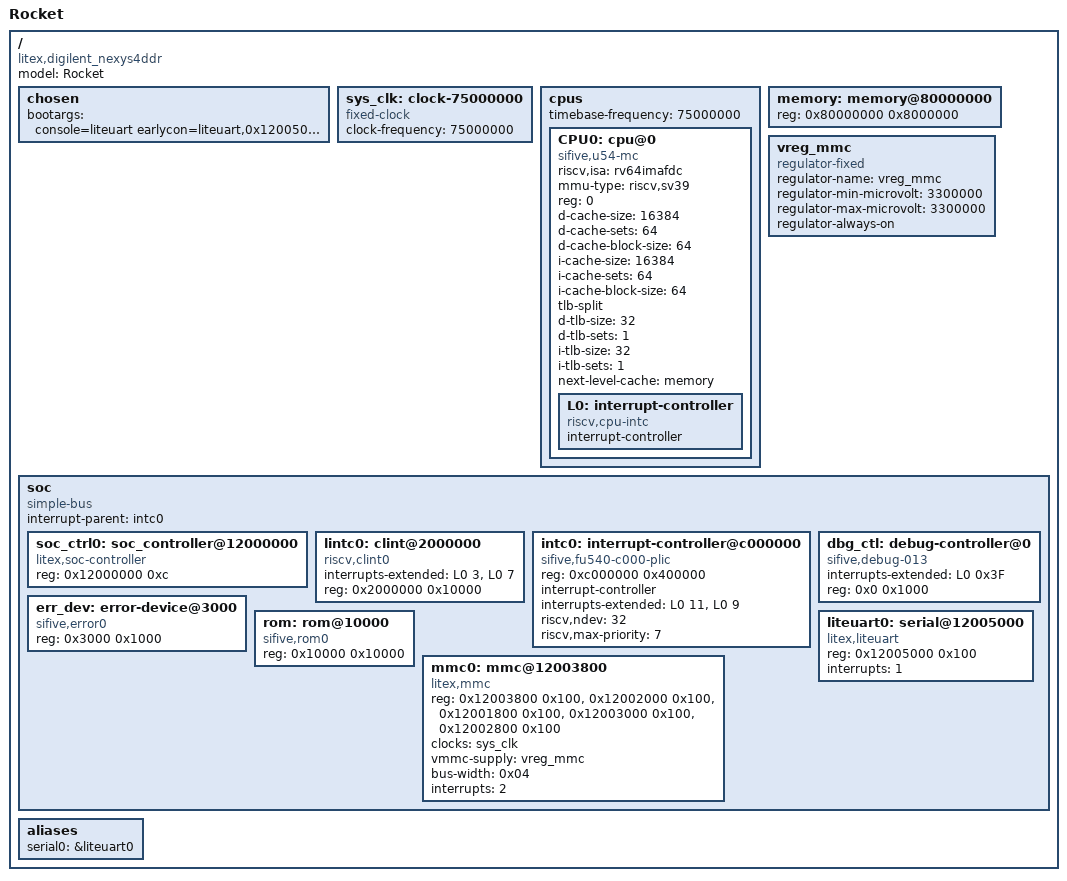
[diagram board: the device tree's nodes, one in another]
/dts-v1/;

/ {
        compatible = "litex,digilent_nexys4ddr", "litex,soc", "sifive,fu540";
        model = "Rocket";
        #address-cells = <1>;
        #size-cells    = <1>;


        chosen {
            bootargs = "console=liteuart earlycon=liteuart,0x12005000 rootwait root=/dev/ram0";
        };

        sys_clk: clock-75000000 {
            compatible = "fixed-clock";
            #clock-cells = <0>;
            clock-frequency  = <75000000>;
        };

        cpus {
            #address-cells = <1>;
            #size-cells    = <0>;
            timebase-frequency = <75000000>;

            CPU0: cpu@0 {
                device_type = "cpu";
                compatible = "sifive,u54-mc", "sifive,rocket0", "riscv";
                riscv,isa = "rv64imafdc";
                mmu-type = "riscv,sv39";
                reg = <0>;

                d-cache-size = <16384>;
                d-cache-sets = <64>;
                d-cache-block-size = <64>;

                i-cache-size = <16384>;
                i-cache-sets = <64>;
                i-cache-block-size = <64>;

                tlb-split;
                d-tlb-size = <32>;
                d-tlb-sets = <1>;

                i-tlb-size = <32>;
                i-tlb-sets = <1>;

                next-level-cache = <&memory>;

                L0: interrupt-controller {
                    #interrupt-cells = <1>;
                    interrupt-controller;
                    compatible = "riscv,cpu-intc";
                };
            };
        };

        memory: memory@80000000 {
            device_type = "memory";
            reg = <0x80000000 0x8000000>;
        };

        vreg_mmc: vreg_mmc {
            compatible = "regulator-fixed";
            regulator-name = "vreg_mmc";
            regulator-min-microvolt = <3300000>;
            regulator-max-microvolt = <3300000>;
            regulator-always-on;
        };

        soc {
            #address-cells = <1>;
            #size-cells    = <1>;
            compatible = "simple-bus";
            interrupt-parent = <&intc0>;
            ranges;

            soc_ctrl0: soc_controller@12000000 {
                compatible = "litex,soc-controller";
                reg = <0x12000000 0xc>;
                status = "okay";
            };

            lintc0: clint@2000000 {
                compatible = "riscv,clint0";
                interrupts-extended = <
                    &L0 3 &L0 7>;
                reg = <0x2000000 0x10000>;
                reg-names = "control";
            };

            intc0: interrupt-controller@c000000 {
                compatible = "sifive,fu540-c000-plic", "sifive,plic-1.0.0";
                reg = <0xc000000 0x400000>;
                #address-cells = <0>;
                #interrupt-cells = <1>;
                interrupt-controller;
                interrupts-extended = <
                    &L0 11 &L0 9>;
                riscv,ndev = <32>;

                reg-names = "control";
                riscv,max-priority = <7>;

            };

            dbg_ctl: debug-controller@0 {
                compatible = "sifive,debug-013", "riscv,debug-013";
                interrupts-extended = <
                    &L0 0x3F>;
                reg = <0x0 0x1000>;
                reg-names = "control";
            };
            err_dev: error-device@3000 {
                compatible = "sifive,error0";
                reg = <0x3000 0x1000>;
            };
            rom: rom@10000 {
                compatible = "sifive,rom0";
                reg = <0x10000 0x10000>;
                reg-names = "mem";
            };

            liteuart0: serial@12005000 {
                compatible = "litex,liteuart";
                reg = <0x12005000 0x100>;
                interrupts = <1>;
                status = "okay";
            };

            mmc0: mmc@12003800 {
                compatible = "litex,mmc";
                reg = <0x12003800 0x100>,
                      <0x12002000 0x100>,
                      <0x12001800 0x100>,
                      <0x12003000 0x100>,
                      <0x12002800 0x100>;
                reg-names = "phy", "core", "reader", "writer", "irq";
                clocks = <&sys_clk>;
                vmmc-supply = <&vreg_mmc>;
                bus-width = <0x04>;
                interrupts = <2>;
                status = "okay";
            };

        };

        aliases {
            serial0 = &liteuart0;
        };

};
